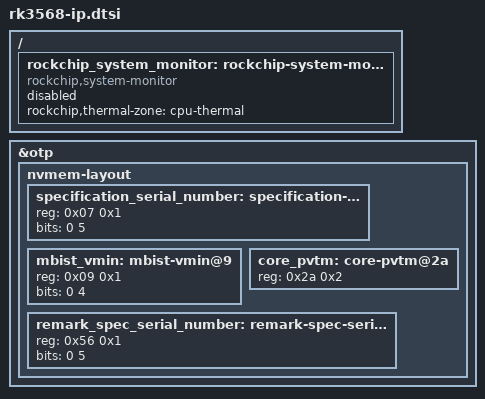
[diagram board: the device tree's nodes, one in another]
/*
 * Copyright (c) 2021 Rockchip Electronics Co., Ltd.
 * Copyright (c) 2025 jjm2473 <jjm2473@gmail.com>
 */

/ {
	rockchip_system_monitor: rockchip-system-monitor {
		compatible = "rockchip,system-monitor";

		rockchip,thermal-zone = "cpu-thermal";
		status = "disabled";
	};

};

&otp {
	nvmem-layout {
		specification_serial_number: specification-serial-number@7 {
			reg = <0x07 0x1>;
			bits = <0 5>;
		};
		mbist_vmin: mbist-vmin@9 {
			reg = <0x09 0x1>;
			bits = <0 4>;
		};
		core_pvtm: core-pvtm@2a {
			reg = <0x2a 0x2>;
		};
		remark_spec_serial_number: remark-spec-serial-number@56 {
			reg = <0x56 0x1>;
			bits = <0 5>;
		};
	};
};

#include "rk3568-vpu.dtsi"
#include "rk3568-gpu.dtsi"
#include "rk3568-npu.dtsi"
#include "rk3568-crypto.dtsi"
